# S32R372 register map
Vendor: Freescale Semiconductor, Inc.; Series: Qorivva; File version: 1.6
Registers are 32-bit, read-write, reset 0x0 unless marked. A register's access mark holds for its fields unless they carry their own. Offsets are from the block's base; [hi:lo] are bit positions; {n}, {i} and the like mark numbered series; <NAME> marks a mode.

## ADC_0 — 12-bit SAR ADC
Base 0xFBE00000; register names take the prefix ADC_0_
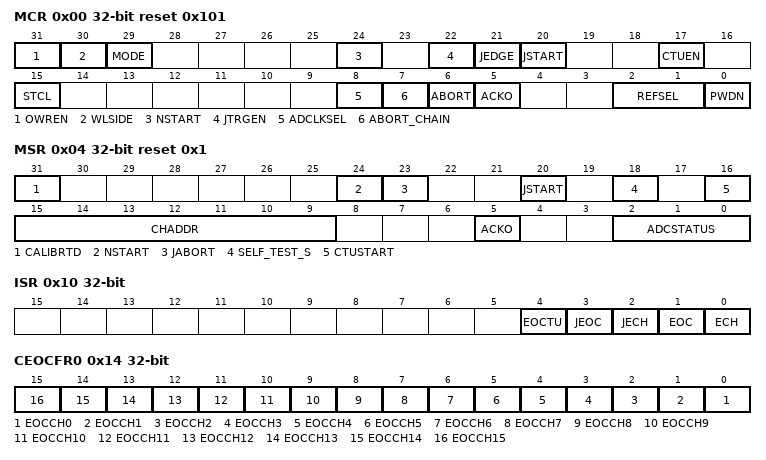
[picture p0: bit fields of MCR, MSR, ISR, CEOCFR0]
0x00 MCR reset 0x101 — Main Configuration Register
  [31] OWREN — Overwrite enable.
    0=Older valid conversion data is not overwritten by newer conversion data; 1=Newer conversion result is always overwritten, irrespective of the validity of older conversion data
  [30] WLSIDE — Write Left/Right aligned.
    0=The conversion data is written right aligned from (32-resolution) to 31); 1=Data is left aligned (from 16 to (16 + resolution - 1)
  [29] MODE — One_Shot/Scan.
    0=One_Shot Mode: configure the Normal conversion of one chain; 1=Scan Mode: configure continuous chain conversion mode; when the programmed chain conversion is finished it restarts immediately
  [24] NSTART — Start of Normal conversion
  [22] JTRGEN — Injection external trigger enable.
  [21] JEDGE — Injection trigger edge selection.
  [20] JSTART — Injection start.
  [17] CTUEN — Crosstrigger Unit Enable.
    0=The crosstriggering unit is disabled and the CTU-triggered injected conversion cannot take place; 1=The crosstriggering unit is enabled and the CTUtriggered injected conversion can take place
  [15] STCL — Self Testing Configuration Lock.
    0=No lock; 1=The self-testing configuration is locked i.e. STCR1, STCR2, STCR3, STBRR, STAW0R, STAW1AR, STAW1BR, STAW2R, STAW4R, STAW5R are write-protected. It can be used only in CPU and SCAN mode. The lock bit is cleared only by a peripheral reset.
  [8] ADCLKSEL — Analog Clock frequency Selector.
    0=ADC clock frequency is half of bus clock; 1=ADC clock frequency is equal to bus clock
  [7] ABORT_CHAIN
  [6] ABORT — Abort Conversion.
  [5] ACKO — Auto clock off enable.
  [2:1] REFSEL — Reference voltage selection for ADC analog part.
    0=Select VREFH as reference voltage
  [0] PWDN — Power-down enable.
0x04 MSR ro reset 0x1 — Main Status register
  [31] CALIBRTD — This bit indicates the ADC calibration status.
    0=Uncalibrated or calibration unsuccessful; 1=Calibration was run and it was successful
  [24] NSTART — This status bit is used to signal that a Normal conversion is ongoing.
  [23] JABORT — This status bit is used to signal that an Injected conversion has been aborted by CTU
  [20] JSTART — This status bit is used to signal that an Injected conversion is ongoing.
  [18] SELF_TEST_S — This status bit signals that self test conversion is ongoing.
  [16] CTUSTART — This status bit is used to signal that a CTU conversion is ongoing.
  [15:9] CHADDR — Channel under measure address.
  [5] ACKO — Auto clock off enable.
  [2:0] ADCSTATUS — Status of the ADC.
    0=Idle; 1=Power Down; 4=Sample; 6=Conversion; 2=Wait state (waiting to start conversion [external trigger]); 3=Busy in Calibration
0x10 ISR — Interrupt Status Register
  [4] EOCTU — End of CTU conversion
  [3] JEOC — End of injected channel conversion.
  [2] JECH — End of injected chain conversion.
  [1] EOC — End of channel conversion.
  [0] ECH — End of chain conversion.
0x14 CEOCFR0 — Channel Pending register 0
  [n] EOCCH{n} (n=0..15) — EOC Channel {n}.
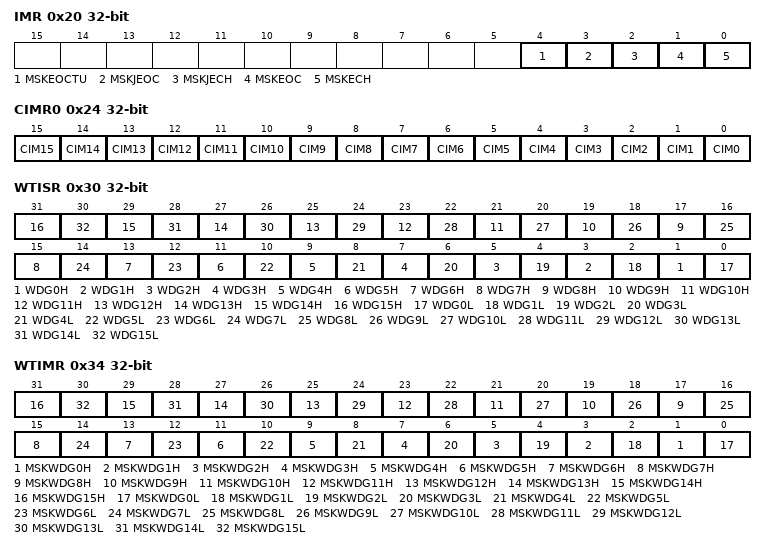
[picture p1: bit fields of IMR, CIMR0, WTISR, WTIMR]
0x20 IMR — Interrupt Mask Register
  [4] MSKEOCTU — Mask bit for EOCTU.
  [3] MSKJEOC — Mask bit for JEOC.
  [2] MSKJECH — Mask bit for JECH.
  [1] MSKEOC — Mask bit for EOC.
  [0] MSKECH — Mask bit for ECH.
0x24 CIMR0 — Channel Interrupt Mask Register 0
  [n] CIM{n} (n=0..15) — Channel {n} interrupt enable.
0x30 WTISR — Watchdog Threshold Interrupt Status Register
  [2n+1] WDG{n}H (n=0..15) — This bit corresponds to the interrupt generated on the converted value being higher than the programmed higher threshold for a channel monitored by Watchdog {n} (WD{n})
  [2n] WDG{n}L (n=0..15) — This bit corresponds to the interrupt generated on the converted value being lower than the programmed lower threshold for a channel monitored by Watchdog {n} (WD{n})
0x34 WTIMR — Watchdog Threshold Interrupt Mask Register
  [2n+1] MSKWDG{n}H (n=0..15) — This bit enables/disables the interrupt generated by the converted value sampled from a channel monitored by Watchdog {n} (WD{n}) being higher than the programmed higher threshold
  [2n] MSKWDG{n}L (n=0..15) — This bit enables/disables the interrupt generated by the converted value sampled from a channel monitored by Watchdog {n} (WD{n}) being lower than the programmed lower threshold
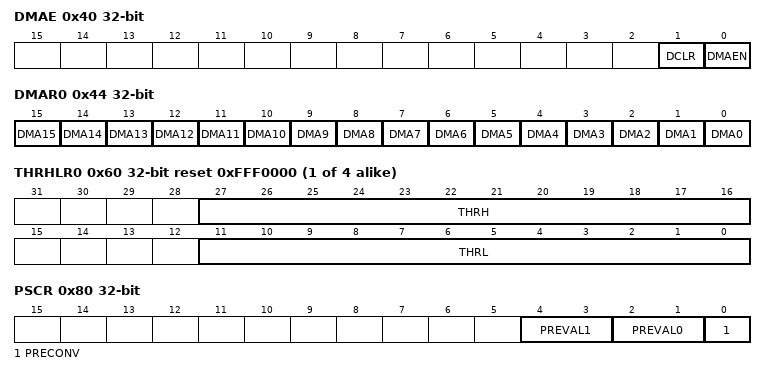
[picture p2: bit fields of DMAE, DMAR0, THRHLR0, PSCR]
0x40 DMAE — DMA Enable register
  [1] DCLR — DMA Clear sequence enable.
    0=DMA request cleared by Acknowledge from DMA controller; 1=DMA request cleared on read of data registers
  [0] DMAEN — DMA global enable.
0x44 DMAR0 — DMA Channel Select Register 0
  [n] DMA{n} (n=0..15) — DMA enable for channel {n}.
{0x60+4i} THRHLR{i} reset 0xFFF0000 (i=0..3) — Threshold Register
  [27:16] THRH — High threshold value for watchdog n.
  [11:0] THRL — Low threshold value for watchdog n.
0x80 PSCR — Presampling Control Register
  [4:3] PREVAL1 — Internal voltage selection for Presampling.
  [2:1] PREVAL0 — Internal voltage selection for Presampling.
  [0] PRECONV — Convert Presampled value
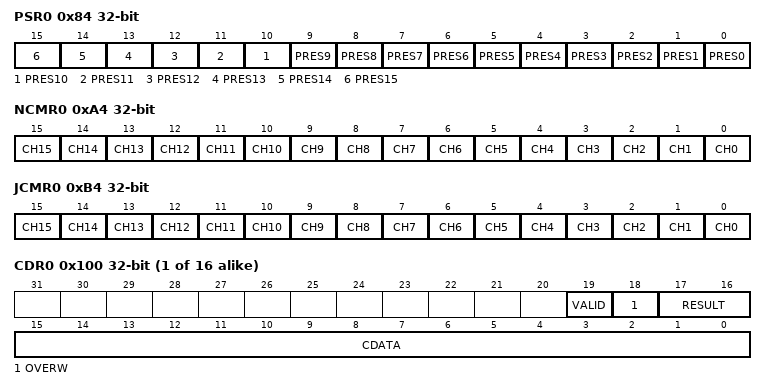
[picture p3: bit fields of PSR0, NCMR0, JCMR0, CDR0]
0x84 PSR0 — Presampling register 0
  [n] PRES{n} (n=0..15) — Presampling enable for channel {n}.
0x94 CTR0 reset 0x16 — Conversion Timing Register 0
  [7:0] INPSAMP — Configuration of sampling phase duration.
0x98 CTR1 reset 0x16 — Conversion Timing Register 1
  [7:0] INPSAMP — Configuration of sampling phase duration.
0xA4 NCMR0 — Normal Conversion Mask Register 0
  [n] CH{n} (n=0..15) — Normal sampling enable for channel {n}.
0xB4 JCMR0 — Injected Conversion Mask Register 0
  [n] CH{n} (n=0..15) — Injected sampling enable for channel {n}.
0xC8 PDEDR — Power Down Exit Delay Register
  [7:0] PDED — The delay between the power down bit reset and the start of conversion
{0x100+4i} CDR{i} (i=0..15) ro — Channel Data Register n (Precision Channels)
  [19] VALID — Used to notify when the data is valid (a new value has been written). It is automatically cleared when data is read.
  [18] OVERW — Overwrite data
  [17:16] RESULT — These two bits reflect the mode of conversion for the corresponding channel.
    0=Data is a result of Normal conversion mode; 1=Data is a result of Injected conversion mode; 2=Data is a result of CTU conversion mode
  [15:0] CDATA — Converted Data 11:0.
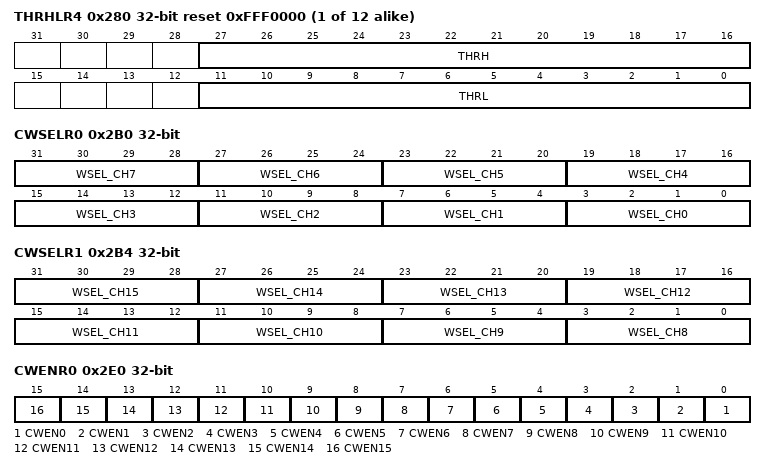
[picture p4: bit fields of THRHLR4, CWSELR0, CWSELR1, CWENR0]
{0x270+4i} THRHLR{i} reset 0xFFF0000 (i=4..15) — Threshold Register
  [27:16] THRH — High threshold value for channel x.
  [11:0] THRL — Low threshold value for channel x.
0x2B0 CWSELR0 — Channel Watchdog Select Register 0
  [4n+3:4n] WSEL_CH{n} (n=0..7) — Channel Watchdog select for channel {n}.
0x2B4 CWSELR1 — Channel Watchdog Select Register 1
  [4n-29:4n-32] WSEL_CH{n} (n=8..15) — Channel Watchdog select for channel {n}.
0x2E0 CWENR0 — Channel Watchdog Enable Register 0
  [n] CWEN{n} (n=0..15) — Watchdog enable for channel {n}.
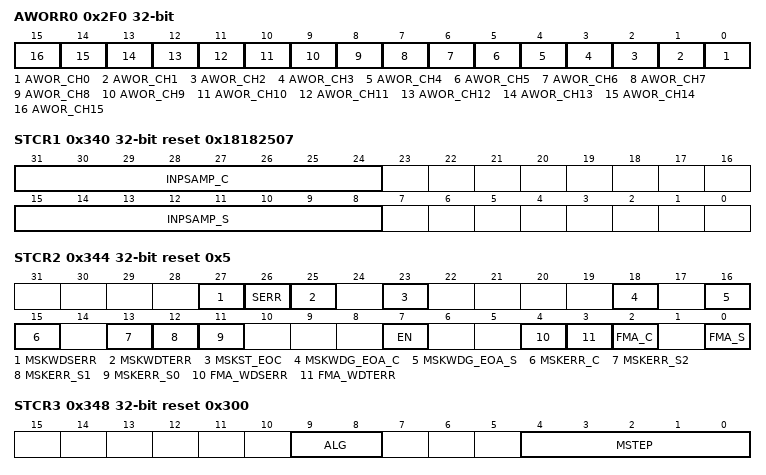
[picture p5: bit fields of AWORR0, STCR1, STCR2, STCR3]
0x2F0 AWORR0 — Analog Watchdog Out of Range Register 0
  [n] AWOR_CH{n} (n=0..15) — Analog watchdog out of range for channel {n}.
0x340 STCR1 reset 0x18182507 — Self Test Configuration Register 1
  [31:24] INPSAMP_C — Sampling phase duration for the test conversions related to self test algorithm C
  [15:8] INPSAMP_S — Sampling phase duration for the test conversions related to self test algorithm S
0x344 STCR2 reset 0x5 — Self Test Configuration Register 2
  [27] MSKWDSERR — Interrupt enable (STSR1[WDSERR] status bit)
    0=Interrupt disabled; 1=Enables the STSR1[WDSERR] status bit to generate an interrupt indication
  [26] SERR wo — Error fault injection bit (write only)
  [25] MSKWDTERR — Interrupt enable (STSR[WDTERR] status bit)
    0=Interrupt disabled; 1=Enables the STSR1[WDTERR] status bit to generate an interrupt indication
  [23] MSKST_EOC — Interrupt Enable bit for STSR2[ST_EOC]
    0=Interrupt disabled; 1=Enables the STSR1[ST_EOC] status bit to generate an interrupt indication. (IMR[MSKEOC] must also be enabled.)
  [18] MSKWDG_EOA_C — Interrupt enable (WDG_EOA_C status bit)
    0=Interrupt disabled; 1=Enables the STSR1[WDG_EOA_C] status bit to generate an interrupt indication
  [16] MSKWDG_EOA_S — Interrupt enable (WDG_EOA_S status bit)
    0=Interrupt disabled; 1=Enables the STSR1[WDG_EOA_S] status bit to generate an interrupt indication
  [15] MSKERR_C — Interrupt enable (ERR_C status bit)
    0=Interrupt disabled; 1=Enables the STSR1[ERR_C] status bit to generate an interrupt indication
  [13] MSKERR_S2 — Interrupt enable (ERR_S2 status bit)
    0=Interrupt disabled; 1=Enables the STSR1[ERR_S2] status bit to generate an interrupt indication
  [12] MSKERR_S1 — Interrupt enable (ERR_S1 status bit)
    0=Interrupt disabled; 1=Enables the STSR1[ERR_S1] status bit to generate an interrupt indication
  [11] MSKERR_S0 — Interrupt enable (ERR_S0 status bit)
    0=Interrupt disabled; 1=Enables the STSR1[ERR_S0] status bit to generate an interrupt indication
  [7] EN — Self testing channel enable. The TEST conversions are enabled.
    0=Disabled; 1=Enabled
  [4] FMA_WDSERR — Fault mapping for the Watchdog Sequence error.
    0=NCF mapping; 1=CF mapping
  [3] FMA_WDTERR — Fault mapping for the Watchdog Timer error.
    0=NCF mapping; 1=CF mapping
  [2] FMA_C — Fault mapping for self test algorithm C.
    0=NCF mapping; 1=CF mapping
  [0] FMA_S — Fault mapping for the self test algorithm BGAP.
    0=NCF mapping; 1=CF mapping
0x348 STCR3 reset 0x300 — Self Test Configuration Register 3
  [9:8] ALG — Algorithm scheduling.
  [4:0] MSTEP — One shot mode: Current step for Algorithm S or Algorithm C
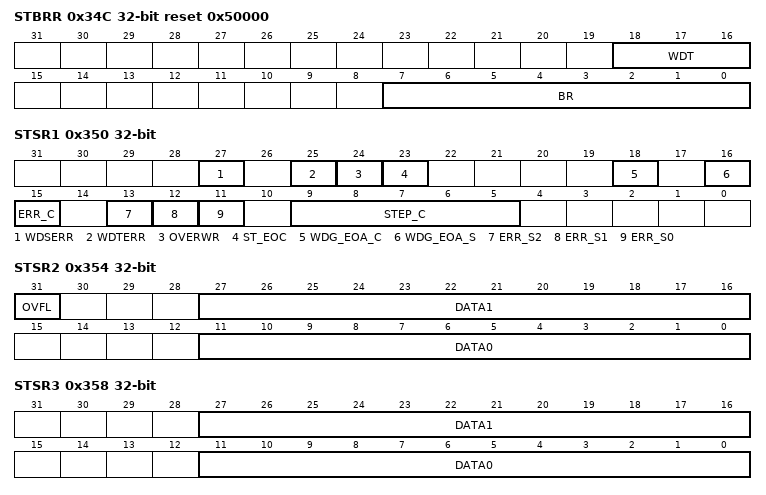
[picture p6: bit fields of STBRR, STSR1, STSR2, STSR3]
0x34C STBRR reset 0x50000 — Self Test Baud Rate Register
  [18:16] WDT — The watchdog timer value is used to monitor that the algorithm sequence is correctly executed within the safe time period
    0=0.1 ms ((0008h * Prescaler) cycles at 80 MHz); 1=0.5 ms ((0027h * Prescaler) cycles at 80 MHz); 2=1 ms ((004Eh * Prescaler) cycles at 80 MHz); 3=2 ms ((009Ch * Prescaler) cycles at 80 MHz); 4=5 ms ((0187h * Prescaler) cycles at 80 MHz); 5=10 ms ((030Dh * Prescaler) cycles at 80 MHz); 6=20 ms ((061Ah * Prescaler) cycles at 80 MHz); 7=50 ms ((0F42h * Prescaler) cycles at 80 MHz)
  [7:0] BR — Baud rate for the selected algorithm in SCAN mode (MCR[MODE] = 1).
0x350 STSR1 — Self Test Status Register 1
  [27] WDSERR — Watchdog sequence error of the ADC sub-system (check for algorithm step sequence)
    0=No failure; 1=Failure occurred
  [25] WDTERR — Watchdog timer error of the ADC sub-system (algorithm check for completion within safe time)
    0=No failure; 1=Failure occurred
  [24] OVERWR — Overwrite error.
  [23] ST_EOC — Self Test EOC Bit.
  [18] WDG_EOA_C — This bit indicates that Algorithm C has been completed
  [16] WDG_EOA_S — This bit indicates that Algorithm S has been completed
  [15] ERR_C — Indicates an error on the self testing channel (algorithm C)
    0=No C-algorithm ERROR; 1=C-algorithm ERROR occurred
  [13] ERR_S2 — Indicates an error on the self testing channel (algorithm SUPPLY, step2)
    0=No ERROR occurred on the sampled signal; 1=ERROR occurred on the sampled signal
  [12] ERR_S1 — Indicates an error on the self testing channel (algorithm SUPPLY, step1)
    0=No VDD ERROR; 1=VDD ERROR occurred
  [11] ERR_S0 — Indicates an error on the self testing channel (algorithm SUPPLY, step0)
    0=No VREF ERROR; 1=VREF ERROR occurred
  [9:5] STEP_C ro — Step of the algorithm C when an ERR_C has occurred.
0x354 STSR2 ro — Self Test Status Register 2
  [31] OVFL — Overflow Bit
  [27:16] DATA1 — Test channel converted data when the ERR_S1 has occurred.
  [11:0] DATA0 — Test channel converted data when the ERR_S1 has occurred.
0x358 STSR3 ro — Self Test Status Register 3
  [27:16] DATA1 — Test channel converted data when the ERR_S2 has occurred.
  [11:0] DATA0 — Test channel converted data when the ERR_S0 has occurred.
0x35C STSR4 ro — Self Test Status Register 4
  [27:16] DATA1 — Test channel converted data when the ERR_C has occurred.
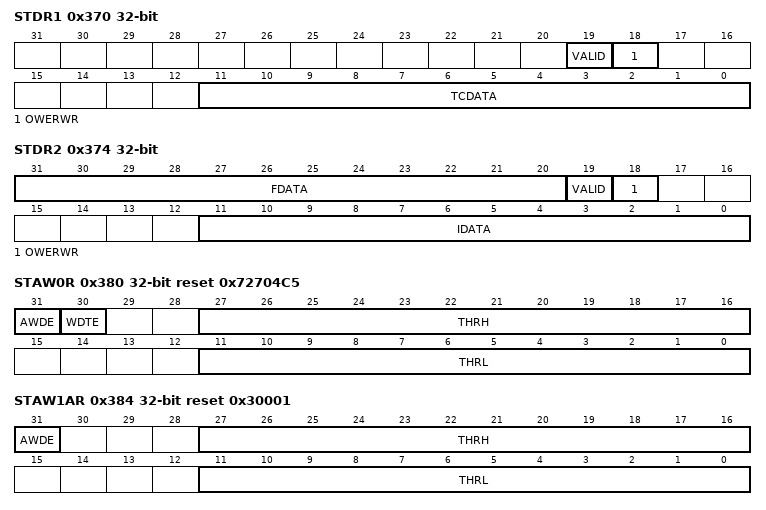
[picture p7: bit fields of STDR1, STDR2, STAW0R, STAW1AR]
0x370 STDR1 ro — Self Test Data Register 1
  [19] VALID — Valid data.
  [18] OWERWR — Overwrite data.
  [11:0] TCDATA — Test channel converted data.
0x374 STDR2 ro — Self Test Data Register 2
  [31:20] FDATA — Fractional part of the ratio TEST(step1)/TEST (step0) = VDD/VBGAP for the algorithm S.
  [19] VALID — Valid data.
  [18] OWERWR — Overwrite data.
  [11:0] IDATA — Integer part of the ratio TEST(step1)/TEST (step0) = VDD/VBGAP for the algorithm S.
0x380 STAW0R reset 0x72704C5 — Self Test Analog Watchdog Register 0
  [31] AWDE — Analog watchdog enable (related to the algorithm S (step 0))
    0=Disabled; 1=Enabled
  [30] WDTE — Watchdog timer enable (related to the algorithm S)
    0=Disabled; 1=Enabled
  [27:16] THRH — High threshold value for Algorithm S step 0
  [11:0] THRL — Low threshold value for Algorithm S step 0
0x384 STAW1AR reset 0x30001 — Self Test Analog Watchdog Register 1A
  [31] AWDE — Analog watchdog enable related to the algorithm S (step1).
  [27:16] THRH — High threshold value (integer part) for test channel for algorithm S (step 1) (unsigned coding).
  [11:0] THRL — Low threshold value (integer part) for test channel for algorithm S (step 1) (unsigned coding).
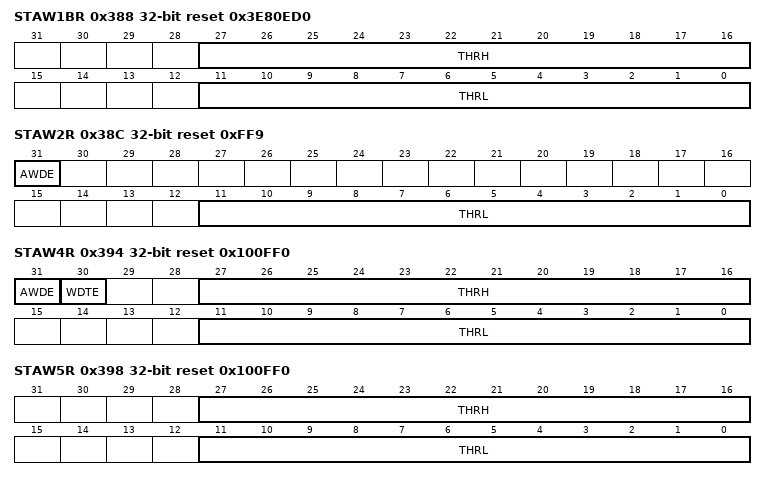
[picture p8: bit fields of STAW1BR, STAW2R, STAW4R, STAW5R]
0x388 STAW1BR reset 0x3E80ED0 — Self Test Analog Watchdog Register 1B
  [27:16] THRH — High threshold value (fractional part) for test channel for algorithm S (step 1)(unsigned coding).
  [11:0] THRL — Low threshold value (fractional part) for test channel for algorithm S (step 1) (unsigned coding).
0x38C STAW2R reset 0xFF9 — Self Test Analog Watchdog Register 2
  [31] AWDE — Analog watchdog enable related to the algorithm S (step2).
  [11:0] THRL — Low threshold value for channel x (unsigned coding). If the analog watchdog is enabled, the STSR1[ERR_S2] status bit is set if STDR1[TCDATA] < THRL.
0x394 STAW4R reset 0x100FF0 — Self Test Analog Watchdog Register 4
  [31] AWDE — Analog watchdog enable (related to the algorithm C)
    0=Disabled; 1=Enabled
  [30] WDTE — Watchdog timer enable (related to the algorithm C).
    0=Disabled; 1=Enabled
  [27:16] THRH — High threshold value for step 0 of C algorithm.
  [11:0] THRL — Low threshold value for step 0 of C algorithm.
0x398 STAW5R reset 0x100FF0 — Self Test Analog Watchdog Register 5
  [27:16] THRH — High threshold value for step N of C algorithm (N = 1 to CS-1).
  [11:0] THRL — Low threshold value for step 0 of C algorithm.
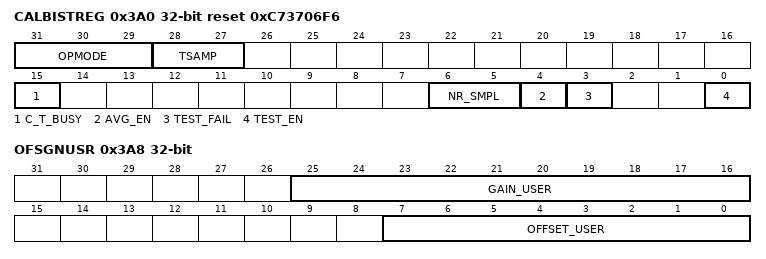
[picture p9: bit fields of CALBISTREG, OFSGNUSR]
0x3A0 CALBISTREG reset 0xC73706F6 — Calibration, BIST Control and status Register
  [31:29] OPMODE — This field specifies the operating mode of the ADC (normal/high accuracy)
    1=12-bit operating mode (normal); 6=12-bit operating mode (high accuracy, recommended)
  [28:27] TSAMP — Test Sample period in Calibration, BIST and Offset calculation process.
    0=22 cycles of ADC clk; 1=8 cycles of ADC clk; 2=16 cycle of ADC clk; 3=32 cycle of ADC clk
  [15] C_T_BUSY ro — This bit indicates that ADC is doing internal operations for BIST or Calibration
    0=ADC is ready for use; 1=ADC is busy in calibration or test operation
  [6:5] NR_SMPL — Number of Samples for averaging.
    0=16 samples; 1=32 samples; 2=128 samples; 3=512 samples
  [4] AVG_EN — Average Enable (for Calibration only).
    0=Disable; 1=Enable
  [3] TEST_FAIL
    0=Test passed; 1=Test failed
  [0] TEST_EN — Enable the test.
    0=Disable the test; 1=Enable the test (self clearing) (once set it cannot be overwritten till it resets)
0x3A8 OFSGNUSR — Offset and Gain User Register
  [25:16] GAIN_USER — Gain User (2's complement format)
  [7:0] OFFSET_USER — Offset User (2's complement format)

## ADC_1 — 12-bit SAR ADC
Base 0xFFE04000; register names take the prefix ADC_1_
Registers as ADC_0.
